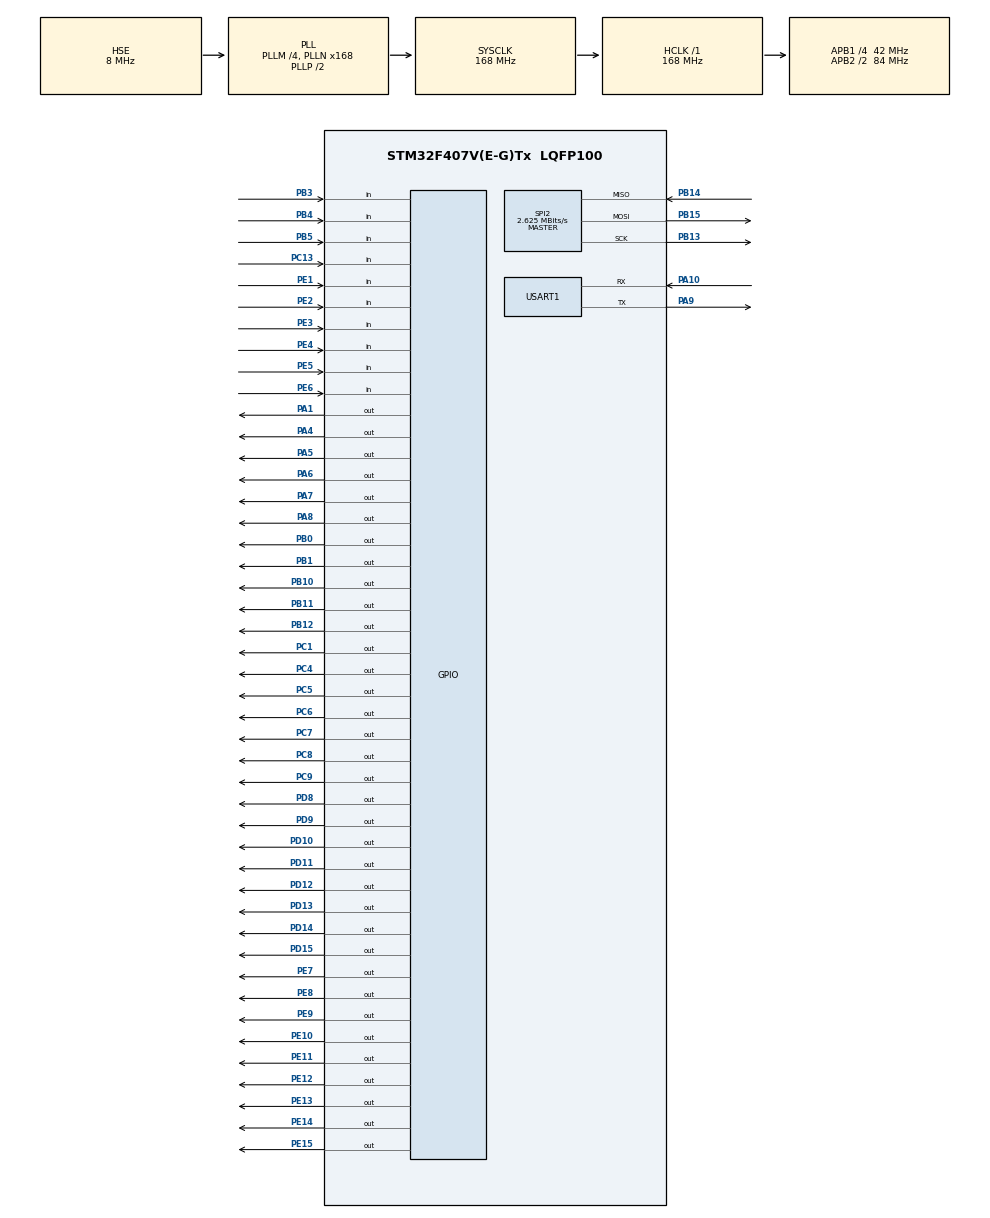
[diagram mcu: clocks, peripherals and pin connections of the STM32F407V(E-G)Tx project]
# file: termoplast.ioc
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Dma.Request0=USART1_RX
Dma.USART1_RX.0.Direction=DMA_PERIPH_TO_MEMORY
Dma.USART1_RX.0.FIFOMode=DMA_FIFOMODE_DISABLE
Dma.USART1_RX.0.Instance=DMA2_Stream2
Dma.USART1_RX.0.MemDataAlignment=DMA_MDATAALIGN_BYTE
Dma.USART1_RX.0.MemInc=DMA_MINC_ENABLE
Dma.USART1_RX.0.Mode=DMA_NORMAL
Dma.USART1_RX.0.PeriphDataAlignment=DMA_PDATAALIGN_BYTE
Dma.USART1_RX.0.PeriphInc=DMA_PINC_DISABLE
Dma.USART1_RX.0.Priority=DMA_PRIORITY_LOW
FREERTOS.Tasks01=defaultTask,24,128,StartDefaultTask,Default,NULL,Static,defaultTaskBuffer,defaultTaskControlBlock;OutputsTask,24,128,StartOutputsTask,As external,NULL,Static,OutputsTaskBuffer,OutputsTaskControlBlock;InputsTask,24,128,StartInputsTask,As external,NULL,Static,InputsTaskBuffer,InputsTaskControlBlock;SteppersTask,24,128,StartSteppersTask,As external,NULL,Static,SteppersTastBuffer,SteppersTastControlBlock;UartWiFiTask,24,256,StartUartWiFiTask,As external,NULL,Static,UartWiFiTaskBuffer,UartWiFiTaskControlBlock;TempSensorTask,24,128,StartTempSensorTask,As external,NULL,Static,TempSensorTaskBuffer,TempSensorTaskControlBlock
IWDG.Prescaler=IWDG_PRESCALER_32
Mcu.Family=STM32F4
Mcu.Name=STM32F407V(E-G)Tx
Mcu.Package=LQFP100
NVIC.DMA2_Stream2_IRQn=true\:5\:0\:false\:false\:true\:true\:false\:true\:true
NVIC.PriorityGroup=NVIC_PRIORITYGROUP_4
NVIC.TIM6_DAC_IRQn=true\:15\:0\:false\:false\:true\:false\:false\:true\:true
NVIC.TimeBase=TIM6_DAC_IRQn
NVIC.TimeBaseIP=TIM6
NVIC.USART1_IRQn=true\:5\:0\:false\:false\:true\:true\:true\:true\:true
PA1.PinState=GPIO_PIN_SET
PA1.Signal=GPIO_Output
PA10.Mode=Asynchronous
PA10.Signal=USART1_RX
PA13.Mode=Serial_Wire
PA13.Signal=SYS_JTMS-SWDIO
PA14.Mode=Serial_Wire
PA14.Signal=SYS_JTCK-SWCLK
PA4.PinState=GPIO_PIN_SET
PA4.Signal=GPIO_Output
PA5.PinState=GPIO_PIN_SET
PA5.Signal=GPIO_Output
PA6.PinState=GPIO_PIN_SET
PA6.Signal=GPIO_Output
PA7.PinState=GPIO_PIN_SET
PA7.Signal=GPIO_Output
PA8.PinState=GPIO_PIN_SET
PA8.Signal=GPIO_Output
PA9.Mode=Asynchronous
PA9.Signal=USART1_TX
PB0.PinState=GPIO_PIN_SET
PB0.Signal=GPIO_Output
PB1.PinState=GPIO_PIN_SET
PB1.Signal=GPIO_Output
PB10.Signal=GPIO_Output
PB11.Signal=GPIO_Output
PB12.Signal=GPIO_Output
PB13.Mode=Full_Duplex_Master
PB13.Signal=SPI2_SCK
PB14.Mode=Full_Duplex_Master
PB14.Signal=SPI2_MISO
PB15.Mode=Full_Duplex_Master
PB15.Signal=SPI2_MOSI
PB3.Signal=GPIO_Input
PB4.Signal=GPIO_Input
PB5.Signal=GPIO_Input
PC1.PinState=GPIO_PIN_SET
PC1.Signal=GPIO_Output
PC13-ANTI_TAMP.Signal=GPIO_Input
PC4.PinState=GPIO_PIN_SET
PC4.Signal=GPIO_Output
PC5.PinState=GPIO_PIN_SET
PC5.Signal=GPIO_Output
PC6.Signal=GPIO_Output
PC7.Signal=GPIO_Output
PC8.Signal=GPIO_Output
PC9.Signal=GPIO_Output
PD10.PinState=GPIO_PIN_SET
PD10.Signal=GPIO_Output
PD11.PinState=GPIO_PIN_SET
PD11.Signal=GPIO_Output
PD12.Signal=GPIO_Output
PD13.Signal=GPIO_Output
PD14.Signal=GPIO_Output
PD15.Signal=GPIO_Output
PD8.PinState=GPIO_PIN_SET
PD8.Signal=GPIO_Output
PD9.PinState=GPIO_PIN_SET
PD9.Signal=GPIO_Output
PE1.Signal=GPIO_Input
PE10.PinState=GPIO_PIN_SET
PE10.Signal=GPIO_Output
PE11.PinState=GPIO_PIN_SET
PE11.Signal=GPIO_Output
PE12.PinState=GPIO_PIN_SET
PE12.Signal=GPIO_Output
PE13.PinState=GPIO_PIN_SET
PE13.Signal=GPIO_Output
PE14.PinState=GPIO_PIN_SET
PE14.Signal=GPIO_Output
PE15.PinState=GPIO_PIN_SET
PE15.Signal=GPIO_Output
PE2.Signal=GPIO_Input
PE3.Signal=GPIO_Input
PE4.Signal=GPIO_Input
PE5.Signal=GPIO_Input
PE6.Signal=GPIO_Input
PE7.PinState=GPIO_PIN_SET
PE7.Signal=GPIO_Output
PE8.PinState=GPIO_PIN_SET
PE8.Signal=GPIO_Output
PE9.PinState=GPIO_PIN_SET
PE9.Signal=GPIO_Output
PH0-OSC_IN.Mode=HSE-External-Oscillator
PH0-OSC_IN.Signal=RCC_OSC_IN
PH1-OSC_OUT.Mode=HSE-External-Oscillator
PH1-OSC_OUT.Signal=RCC_OSC_OUT
ProjectManager.HeapSize=0x200
ProjectManager.StackSize=0x400
ProjectManager.TargetToolchain=STM32CubeIDE
RCC.48MHZClocksFreq_Value=84000000
RCC.AHBFreq_Value=168000000
RCC.APB1CLKDivider=RCC_HCLK_DIV4
RCC.APB1Freq_Value=42000000
RCC.APB1TimFreq_Value=84000000
RCC.APB2CLKDivider=RCC_HCLK_DIV2
RCC.APB2Freq_Value=84000000
RCC.APB2TimFreq_Value=168000000
RCC.CortexFreq_Value=168000000
RCC.HCLKFreq_Value=168000000
RCC.HSE_VALUE=8000000
RCC.HSI_VALUE=16000000
RCC.LSE_VALUE=32768
RCC.PLLM=4
RCC.PLLN=168
RCC.PLLSourceVirtual=RCC_PLLSOURCE_HSE
RCC.SYSCLKFreq_VALUE=168000000
RCC.SYSCLKSource=RCC_SYSCLKSOURCE_PLLCLK
RCC.VCOOutputFreq_Value=336000000
SPI2.BaudRatePrescaler=SPI_BAUDRATEPRESCALER_16
SPI2.CalculateBaudRate=2.625 MBits/s
SPI2.Direction=SPI_DIRECTION_2LINES
SPI2.Mode=SPI_MODE_MASTER
SPI2.VirtualType=VM_MASTER
TIM2.Period=65535
TIM2.Prescaler=71
USART1.VirtualMode=VM_ASYNC
VP_FREERTOS_VS_CMSIS_V2.Mode=CMSIS_V2
VP_IWDG_VS_IWDG.Mode=IWDG_Activate
VP_SYS_VS_tim6.Mode=TIM6
VP_TIM2_VS_ClockSourceINT.Mode=Internal
board=custom

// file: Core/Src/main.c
/* USER CODE BEGIN Header */
/**
  ******************************************************************************
  * @file           : main.c
  * @brief          : Main program body
  ******************************************************************************
  * @attention
  *
  * Copyright (c) 2023 STMicroelectronics.
  * All rights reserved.
  *
  * This software is licensed under terms that can be found in the LICENSE file
  * in the root directory of this software component.
  * If no LICENSE file comes with this software, it is provided AS-IS.
  *
  ******************************************************************************
  */
/* USER CODE END Header */
#include "main.h"
#include "cmsis_os.h"
#include "dma.h"
#include "iwdg.h"
#include "spi.h"
#include "tim.h"
#include "usart.h"
#include "gpio.h"

void SystemClock_Config(void);
void MX_FREERTOS_Init(void);

int main(void)
{

  /* MCU Configuration--------------------------------------------------------*/

  /* Reset of all peripherals, Initializes the Flash interface and the Systick. */
  HAL_Init();

  /* Configure the system clock */
  SystemClock_Config();

  /* Initialize all configured peripherals */
  MX_GPIO_Init();
  MX_DMA_Init();
  MX_TIM2_Init();
  MX_USART1_UART_Init();
  MX_SPI2_Init();
  MX_IWDG_Init();

  /* Init scheduler */
  osKernelInitialize();  /* Call init function for freertos objects (in freertos.c) */
  MX_FREERTOS_Init();

  /* Start scheduler */
  osKernelStart();

  /* We should never get here as control is now taken by the scheduler */
  /* Infinite loop */
  while (1)
  {

  }
}

void SystemClock_Config(void)
{
  RCC_OscInitTypeDef RCC_OscInitStruct = {0};
  RCC_ClkInitTypeDef RCC_ClkInitStruct = {0};

  /** Configure the main internal regulator output voltage
  */
  __HAL_RCC_PWR_CLK_ENABLE();
  __HAL_PWR_VOLTAGESCALING_CONFIG(PWR_REGULATOR_VOLTAGE_SCALE1);

  /** Initializes the RCC Oscillators according to the specified parameters
  * in the RCC_OscInitTypeDef structure.
  */
  RCC_OscInitStruct.OscillatorType = RCC_OSCILLATORTYPE_LSI|RCC_OSCILLATORTYPE_HSE;
  RCC_OscInitStruct.HSEState = RCC_HSE_ON;
  RCC_OscInitStruct.LSIState = RCC_LSI_ON;
  RCC_OscInitStruct.PLL.PLLState = RCC_PLL_ON;
  RCC_OscInitStruct.PLL.PLLSource = RCC_PLLSOURCE_HSE;
  RCC_OscInitStruct.PLL.PLLM = 4;
  RCC_OscInitStruct.PLL.PLLN = 168;
  RCC_OscInitStruct.PLL.PLLP = RCC_PLLP_DIV2;
  RCC_OscInitStruct.PLL.PLLQ = 4;
  if (HAL_RCC_OscConfig(&RCC_OscInitStruct) != HAL_OK)
  {
    Error_Handler();
  }

  /** Initializes the CPU, AHB and APB buses clocks
  */
  RCC_ClkInitStruct.ClockType = RCC_CLOCKTYPE_HCLK|RCC_CLOCKTYPE_SYSCLK
                              |RCC_CLOCKTYPE_PCLK1|RCC_CLOCKTYPE_PCLK2;
  RCC_ClkInitStruct.SYSCLKSource = RCC_SYSCLKSOURCE_PLLCLK;
  RCC_ClkInitStruct.AHBCLKDivider = RCC_SYSCLK_DIV1;
  RCC_ClkInitStruct.APB1CLKDivider = RCC_HCLK_DIV4;
  RCC_ClkInitStruct.APB2CLKDivider = RCC_HCLK_DIV2;

  if (HAL_RCC_ClockConfig(&RCC_ClkInitStruct, FLASH_LATENCY_5) != HAL_OK)
  {
    Error_Handler();
  }
}

void HAL_TIM_PeriodElapsedCallback(TIM_HandleTypeDef *htim)
{
  if (htim->Instance == TIM6) {
    HAL_IncTick();
  }
}

void Error_Handler(void)
{
  __disable_irq();
  while (1)
  {
  }
}

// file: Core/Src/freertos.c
/* USER CODE BEGIN Header */
/**
  ******************************************************************************
  * File Name          : freertos.c
  * Description        : Code for freertos applications
  ******************************************************************************
  * @attention
  *
  * Copyright (c) 2023 STMicroelectronics.
  * All rights reserved.
  *
  * This software is licensed under terms that can be found in the LICENSE file
  * in the root directory of this software component.
  * If no LICENSE file comes with this software, it is provided AS-IS.
  *
  ******************************************************************************
  */
/* USER CODE END Header */

#include "FreeRTOS.h"
#include "task.h"
#include "main.h"
#include "cmsis_os.h"

/* USER CODE BEGIN Includes */

#include "termoplast_config.h"
#include "outputs.h"
#include "inputs.h"
#include "stepper_control.h"
#include "uart_wifi.h"
#include "temp_sensor.h"

/* USER CODE END Includes */

typedef StaticTask_t osStaticThreadDef_t;

/* USER CODE BEGIN Variables */

GlobDataTypeDef globData;
TermoplastConfigTypeDef termoplastConfig;

/* USER CODE END Variables */
/* Definitions for defaultTask */
osThreadId_t defaultTaskHandle;
uint32_t defaultTaskBuffer[ 128 ];
osStaticThreadDef_t defaultTaskControlBlock;
const osThreadAttr_t defaultTask_attributes = {
  .name = "defaultTask",
  .cb_mem = &defaultTaskControlBlock,
  .cb_size = sizeof(defaultTaskControlBlock),
  .stack_mem = &defaultTaskBuffer[0],
  .stack_size = sizeof(defaultTaskBuffer),
  .priority = (osPriority_t) osPriorityNormal,
};
/* Definitions for OutputsTask */
osThreadId_t OutputsTaskHandle;
uint32_t OutputsTaskBuffer[ 128 ];
osStaticThreadDef_t OutputsTaskControlBlock;
const osThreadAttr_t OutputsTask_attributes = {
  .name = "OutputsTask",
  .cb_mem = &OutputsTaskControlBlock,
  .cb_size = sizeof(OutputsTaskControlBlock),
  .stack_mem = &OutputsTaskBuffer[0],
  .stack_size = sizeof(OutputsTaskBuffer),
  .priority = (osPriority_t) osPriorityNormal,
};
/* Definitions for InputsTask */
osThreadId_t InputsTaskHandle;
uint32_t InputsTaskBuffer[ 128 ];
osStaticThreadDef_t InputsTaskControlBlock;
const osThreadAttr_t InputsTask_attributes = {
  .name = "InputsTask",
  .cb_mem = &InputsTaskControlBlock,
  .cb_size = sizeof(InputsTaskControlBlock),
  .stack_mem = &InputsTaskBuffer[0],
  .stack_size = sizeof(InputsTaskBuffer),
  .priority = (osPriority_t) osPriorityNormal,
};
/* Definitions for SteppersTask */
osThreadId_t SteppersTaskHandle;
uint32_t SteppersTastBuffer[ 128 ];
osStaticThreadDef_t SteppersTastControlBlock;
const osThreadAttr_t SteppersTask_attributes = {
  .name = "SteppersTask",
  .cb_mem = &SteppersTastControlBlock,
  .cb_size = sizeof(SteppersTastControlBlock),
  .stack_mem = &SteppersTastBuffer[0],
  .stack_size = sizeof(SteppersTastBuffer),
  .priority = (osPriority_t) osPriorityNormal,
};
/* Definitions for UartWiFiTask */
osThreadId_t UartWiFiTaskHandle;
uint32_t UartWiFiTaskBuffer[ 256 ];
osStaticThreadDef_t UartWiFiTaskControlBlock;
const osThreadAttr_t UartWiFiTask_attributes = {
  .name = "UartWiFiTask",
  .cb_mem = &UartWiFiTaskControlBlock,
  .cb_size = sizeof(UartWiFiTaskControlBlock),
  .stack_mem = &UartWiFiTaskBuffer[0],
  .stack_size = sizeof(UartWiFiTaskBuffer),
  .priority = (osPriority_t) osPriorityNormal,
};
/* Definitions for TempSensorTask */
osThreadId_t TempSensorTaskHandle;
uint32_t TempSensorTaskBuffer[ 128 ];
osStaticThreadDef_t TempSensorTaskControlBlock;
const osThreadAttr_t TempSensorTask_attributes = {
  .name = "TempSensorTask",
  .cb_mem = &TempSensorTaskControlBlock,
  .cb_size = sizeof(TempSensorTaskControlBlock),
  .stack_mem = &TempSensorTaskBuffer[0],
  .stack_size = sizeof(TempSensorTaskBuffer),
  .priority = (osPriority_t) osPriorityNormal,
};

void StartDefaultTask(void *argument);
extern void StartOutputsTask(void *argument);
extern void StartInputsTask(void *argument);
extern void StartSteppersTask(void *argument);
extern void StartUartWiFiTask(void *argument);
extern void StartTempSensorTask(void *argument);

void MX_FREERTOS_Init(void); /* (MISRA C 2004 rule 8.1) */

void MX_FREERTOS_Init(void) {

  /* Create the thread(s) */
  /* creation of defaultTask */
  defaultTaskHandle = osThreadNew(StartDefaultTask, NULL, &defaultTask_attributes);

  /* creation of OutputsTask */
  OutputsTaskHandle = osThreadNew(StartOutputsTask, NULL, &OutputsTask_attributes);

  /* creation of InputsTask */
  InputsTaskHandle = osThreadNew(StartInputsTask, NULL, &InputsTask_attributes);

  /* creation of SteppersTask */
  SteppersTaskHandle = osThreadNew(StartSteppersTask, NULL, &SteppersTask_attributes);

  /* creation of UartWiFiTask */
  UartWiFiTaskHandle = osThreadNew(StartUartWiFiTask, NULL, &UartWiFiTask_attributes);

  /* creation of TempSensorTask */
  TempSensorTaskHandle = osThreadNew(StartTempSensorTask, NULL, &TempSensorTask_attributes);

}

void StartDefaultTask(void *argument)
{
  /* USER CODE BEGIN StartDefaultTask */
  /* Infinite loop */
  for(;;)
  {
	HAL_GPIO_TogglePin(GPIOD, GPIO_PIN_11);
    osDelay(1000);
  }
  /* USER CODE END StartDefaultTask */
}
